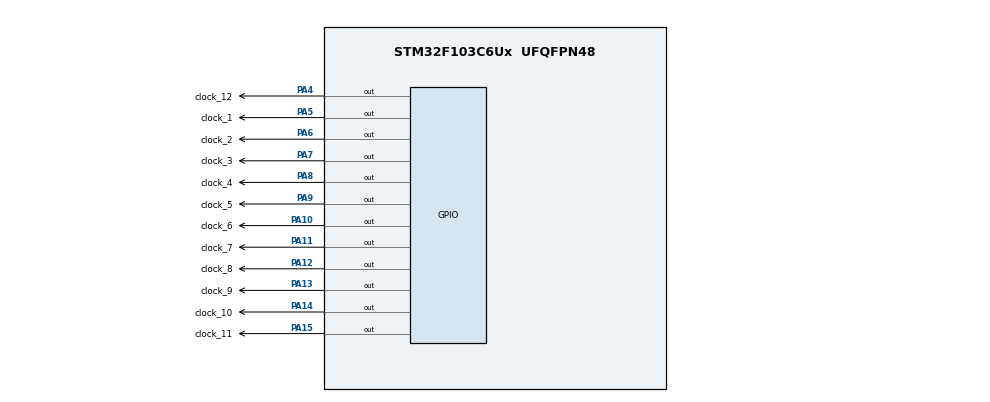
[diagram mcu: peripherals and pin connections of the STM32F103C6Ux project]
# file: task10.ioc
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Mcu.Family=STM32F1
Mcu.Name=STM32F103C6Ux
Mcu.Package=UFQFPN48
NVIC.PriorityGroup=NVIC_PRIORITYGROUP_4
PA10.GPIO_Label=clock_6
PA10.Signal=GPIO_Output
PA11.GPIO_Label=clock_7
PA11.Signal=GPIO_Output
PA12.GPIO_Label=clock_8
PA12.Signal=GPIO_Output
PA13.GPIO_Label=clock_9
PA13.Signal=GPIO_Output
PA14.GPIO_Label=clock_10
PA14.Signal=GPIO_Output
PA15.GPIO_Label=clock_11
PA15.Signal=GPIO_Output
PA4.GPIO_Label=clock_12
PA4.Signal=GPIO_Output
PA5.GPIO_Label=clock_1
PA5.Signal=GPIO_Output
PA6.GPIO_Label=clock_2
PA6.Signal=GPIO_Output
PA7.GPIO_Label=clock_3
PA7.Signal=GPIO_Output
PA8.GPIO_Label=clock_4
PA8.Signal=GPIO_Output
PA9.GPIO_Label=clock_5
PA9.Signal=GPIO_Output
ProjectManager.HeapSize=0x200
ProjectManager.StackSize=0x400
ProjectManager.TargetToolchain=STM32CubeIDE
RCC.APB1Freq_Value=8000000
RCC.APB2Freq_Value=8000000
VP_SYS_VS_ND.Mode=No_Debug
board=custom

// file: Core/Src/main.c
/* USER CODE BEGIN Header */
/**
  ******************************************************************************
  * @file           : main.c
  * @brief          : Main program body
  ******************************************************************************
  * @attention
  *
  * <h2><center>&copy; Copyright (c) 2026 STMicroelectronics.
  * All rights reserved.</center></h2>
  *
  * This software component is licensed by ST under BSD 3-Clause license,
  * the "License"; You may not use this file except in compliance with the
  * License. You may obtain a copy of the License at:
  *                        opensource.org/licenses/BSD-3-Clause
  *
  ******************************************************************************
  */
/* USER CODE END Header */
#include "main.h"

void SystemClock_Config(void);
static void MX_GPIO_Init(void);

void clearAllClock(){
	HAL_GPIO_WritePin(clock_1_GPIO_Port, clock_1_Pin|
										clock_2_Pin|
										clock_3_Pin|
										clock_4_Pin|
										clock_5_Pin|
										clock_6_Pin|
										clock_7_Pin|
										clock_8_Pin|
										clock_9_Pin|
										clock_10_Pin|
										clock_11_Pin|
										clock_12_Pin, RESET);

}
void setNumberOnClock(int num){
	switch(num){
	case 1:
		HAL_GPIO_WritePin(clock_1_GPIO_Port, clock_1_Pin, SET);
		break;
	case 2:
		HAL_GPIO_WritePin(clock_2_GPIO_Port, clock_2_Pin, SET);
		break;
	case 3:
		HAL_GPIO_WritePin(clock_3_GPIO_Port, clock_3_Pin, SET);
		break;
	case 4:
		HAL_GPIO_WritePin(clock_4_GPIO_Port, clock_4_Pin, SET);
		break;
	case 5:
		HAL_GPIO_WritePin(clock_5_GPIO_Port, clock_5_Pin, SET);
		break;
	case 6:
		HAL_GPIO_WritePin(clock_6_GPIO_Port, clock_6_Pin, SET);
		break;
	case 7:
		HAL_GPIO_WritePin(clock_7_GPIO_Port, clock_7_Pin, SET);
		break;
	case 8:
		HAL_GPIO_WritePin(clock_8_GPIO_Port, clock_8_Pin, SET);
		break;
	case 9:
		HAL_GPIO_WritePin(clock_9_GPIO_Port, clock_9_Pin, SET);
		break;
	case 10:
		HAL_GPIO_WritePin(clock_10_GPIO_Port, clock_10_Pin, SET);
		break;
	case 11:
		HAL_GPIO_WritePin(clock_11_GPIO_Port, clock_11_Pin, SET);
		break;
	case 0:
		HAL_GPIO_WritePin(clock_12_GPIO_Port, clock_12_Pin, SET);
		break;
	}
}
void clearNumberOnClock(int num){
	switch(num){
		case 1:
			HAL_GPIO_WritePin(clock_1_GPIO_Port, clock_1_Pin, RESET);
			break;
		case 2:
			HAL_GPIO_WritePin(clock_2_GPIO_Port, clock_2_Pin, RESET);
			break;
		case 3:
			HAL_GPIO_WritePin(clock_3_GPIO_Port, clock_3_Pin, RESET);
			break;
		case 4:
			HAL_GPIO_WritePin(clock_4_GPIO_Port, clock_4_Pin, RESET);
			break;
		case 5:
			HAL_GPIO_WritePin(clock_5_GPIO_Port, clock_5_Pin, RESET);
			break;
		case 6:
			HAL_GPIO_WritePin(clock_6_GPIO_Port, clock_6_Pin, RESET);
			break;
		case 7:
			HAL_GPIO_WritePin(clock_7_GPIO_Port, clock_7_Pin, RESET);
			break;
		case 8:
			HAL_GPIO_WritePin(clock_8_GPIO_Port, clock_8_Pin, RESET);
			break;
		case 9:
			HAL_GPIO_WritePin(clock_9_GPIO_Port, clock_9_Pin, RESET);
			break;
		case 10:
			HAL_GPIO_WritePin(clock_10_GPIO_Port, clock_10_Pin, RESET);
			break;
		case 11:
			HAL_GPIO_WritePin(clock_11_GPIO_Port, clock_11_Pin, RESET);
			break;
		case 0:
			HAL_GPIO_WritePin(clock_12_GPIO_Port, clock_12_Pin, RESET);
			break;
		}
}
uint8_t currentHour   = 0;
uint8_t currentMinute = 0;
uint8_t currentSecond = 0;

uint32_t lastTick = 0;
void updateClockDisplay(void){
	clearAllClock();
	uint8_t hourPos = currentHour % 12;
	uint8_t minutePos = currentMinute / 5;
	uint8_t secondPos = currentSecond / 5;
	setNumberOnClock(hourPos);
	setNumberOnClock(minutePos);
	setNumberOnClock(secondPos);
}
void updateTime(void){
	currentSecond++;
	if(currentSecond >= 60){
		currentMinute++;
		currentSecond = 0;
		if(currentMinute >= 60){
			currentMinute = 0;
			currentHour++;
			if(currentHour >= 24){
				currentHour = 0;
			}
		}
	}
}
int main(void)
{

  /* MCU Configuration--------------------------------------------------------*/

  /* Reset of all peripherals, Initializes the Flash interface and the Systick. */
  HAL_Init();

  /* Configure the system clock */
  SystemClock_Config();

  /* Initialize all configured peripherals */
  MX_GPIO_Init();

  /* Infinite loop */
  /* USER CODE BEGIN WHILE */
  lastTick = HAL_GetTick();
  updateClockDisplay();
  while (1)
  {
    /* USER CODE END WHILE */
	  if(HAL_GetTick() - lastTick >= 1000){
		  lastTick += 1000;
		  updateTime();
		  updateClockDisplay();
	  }
  }
}

void SystemClock_Config(void)
{
  RCC_OscInitTypeDef RCC_OscInitStruct = {0};
  RCC_ClkInitTypeDef RCC_ClkInitStruct = {0};

  /** Initializes the RCC Oscillators according to the specified parameters
  * in the RCC_OscInitTypeDef structure.
  */
  RCC_OscInitStruct.OscillatorType = RCC_OSCILLATORTYPE_HSI;
  RCC_OscInitStruct.HSIState = RCC_HSI_ON;
  RCC_OscInitStruct.HSICalibrationValue = RCC_HSICALIBRATION_DEFAULT;
  RCC_OscInitStruct.PLL.PLLState = RCC_PLL_NONE;
  if (HAL_RCC_OscConfig(&RCC_OscInitStruct) != HAL_OK)
  {
    Error_Handler();
  }
  /** Initializes the CPU, AHB and APB buses clocks
  */
  RCC_ClkInitStruct.ClockType = RCC_CLOCKTYPE_HCLK|RCC_CLOCKTYPE_SYSCLK
                              |RCC_CLOCKTYPE_PCLK1|RCC_CLOCKTYPE_PCLK2;
  RCC_ClkInitStruct.SYSCLKSource = RCC_SYSCLKSOURCE_HSI;
  RCC_ClkInitStruct.AHBCLKDivider = RCC_SYSCLK_DIV1;
  RCC_ClkInitStruct.APB1CLKDivider = RCC_HCLK_DIV1;
  RCC_ClkInitStruct.APB2CLKDivider = RCC_HCLK_DIV1;

  if (HAL_RCC_ClockConfig(&RCC_ClkInitStruct, FLASH_LATENCY_0) != HAL_OK)
  {
    Error_Handler();
  }
}

static void MX_GPIO_Init(void)
{
  GPIO_InitTypeDef GPIO_InitStruct = {0};

  /* GPIO Ports Clock Enable */
  __HAL_RCC_GPIOA_CLK_ENABLE();

  /*Configure GPIO pin Output Level */
  HAL_GPIO_WritePin(GPIOA, clock_12_Pin|clock_1_Pin|clock_2_Pin|clock_3_Pin
                          |clock_4_Pin|clock_5_Pin|clock_6_Pin|clock_7_Pin
                          |clock_8_Pin|clock_9_Pin|clock_10_Pin|clock_11_Pin, GPIO_PIN_RESET);

  /*Configure GPIO pins : clock_12_Pin clock_1_Pin clock_2_Pin clock_3_Pin
                           clock_4_Pin clock_5_Pin clock_6_Pin clock_7_Pin
                           clock_8_Pin clock_9_Pin clock_10_Pin clock_11_Pin */
  GPIO_InitStruct.Pin = clock_12_Pin|clock_1_Pin|clock_2_Pin|clock_3_Pin
                          |clock_4_Pin|clock_5_Pin|clock_6_Pin|clock_7_Pin
                          |clock_8_Pin|clock_9_Pin|clock_10_Pin|clock_11_Pin;
  GPIO_InitStruct.Mode = GPIO_MODE_OUTPUT_PP;
  GPIO_InitStruct.Pull = GPIO_NOPULL;
  GPIO_InitStruct.Speed = GPIO_SPEED_FREQ_LOW;
  HAL_GPIO_Init(GPIOA, &GPIO_InitStruct);

}

void Error_Handler(void)
{
  __disable_irq();
  while (1)
  {
  }
}

/************************ (C) COPYRIGHT STMicroelectronics *****END OF FILE****/
